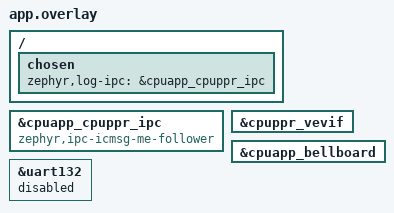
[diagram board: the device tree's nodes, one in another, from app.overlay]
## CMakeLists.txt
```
#
# Copyright (c) 2026 Nordic Semiconductor ASA
#
# SPDX-License-Identifier: LicenseRef-Nordic-5-Clause
#

cmake_minimum_required(VERSION 3.20.0)

find_package(Zephyr REQUIRED HINTS $ENV{ZEPHYR_BASE})
project("Asset Tracker Template PPR")

target_sources(app PRIVATE src/main.c)
```

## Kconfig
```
#
# Copyright (c) 2026 Nordic Semiconductor ASA
#
# SPDX-License-Identifier: LicenseRef-Nordic-5-Clause
#

config PPR_HELLO_INTERVAL_SECONDS
	int "Hello world interval (seconds)"
	default 5
	help
	  Interval between the "hello world" log messages printed by the PPR core.

source "Kconfig.zephyr"
```

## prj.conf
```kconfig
#
# Copyright (c) 2026 Nordic Semiconductor ASA
#
# SPDX-License-Identifier: LicenseRef-Nordic-5-Clause
#

# Logs are forwarded to the application core over IPC (icmsg-me).
CONFIG_LOG=y
CONFIG_LOG_BACKEND_IPC_SERVICE=y
CONFIG_IPC_SERVICE=y
CONFIG_MBOX=y
CONFIG_OPENAMP=n
CONFIG_PM=n

# Name reported to the application core, used as the "cpuppr/" log line prefix.
CONFIG_LOG_DOMAIN_NAME="cpuppr"

# Must run after the icmsg workqueue is started (CONFIG_KERNEL_INIT_PRIORITY_DEFAULT).
# The backend enables the mbox RX callback at init, and an interrupt before the
# workqueue exists trips an assert in icmsg.c.
CONFIG_LOG_CORE_INIT_PRIORITY=47

# Keep RAM use low, the PPR runs from its 64 KB TCM (CONFIG_XIP=n).
#
# Deferred log mode (the default) is required: the IPC backend only becomes ready
# after an asynchronous handshake with the application core, and only the log
# processing thread retries activating it.
CONFIG_LOG_BUFFER_SIZE=256
CONFIG_LOG_PROCESS_THREAD_STACK_SIZE=640
CONFIG_HEAP_MEM_POOL_SIZE=256

# Output goes over IPC only. No UART console on the PPR.
CONFIG_SERIAL=n
CONFIG_CONSOLE=n
CONFIG_UART_CONSOLE=n
```

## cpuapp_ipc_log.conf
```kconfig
#
# Copyright (c) 2026 Nordic Semiconductor ASA
#
# SPDX-License-Identifier: LicenseRef-Nordic-5-Clause
#

# Application core side of the PPR log forwarding. Added to the application image
# by app/sysbuild.cmake when SB_CONFIG_LAUNCH_PPR is enabled.

CONFIG_LOG=y
CONFIG_LOG_MULTIDOMAIN=y
CONFIG_LOG_LINK_IPC_SERVICE=y
CONFIG_IPC_SERVICE=y
CONFIG_MBOX=y

# Prefix each log line with the core it came from ("cpuapp/" or "cpuppr/").
# The PPR core's name is fetched over the same IPC link.
CONFIG_LOG_DOMAIN_NAME_PREFIX=y
CONFIG_LOG_DOMAIN_NAME="cpuapp"

# The log link init must run after both the VPR launcher that starts the PPR core
# (CONFIG_NORDIC_VPR_LAUNCHER_INIT_PRIORITY, default 0) and the icmsg-me backend
# init (CONFIG_IPC_SERVICE_REG_BACKEND_PRIORITY, default 46). Otherwise the link
# waits forever for a core that was never launched, or races the backend init.
CONFIG_LOG_CORE_INIT_PRIORITY=47
```

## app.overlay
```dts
/*
 * Copyright (c) 2026 Nordic Semiconductor ASA
 *
 * SPDX-License-Identifier: LicenseRef-Nordic-5-Clause
 */

/* Follower side of the icmsg-me log channel, see ../cpuapp_ipc_log.overlay. */
&cpuapp_cpuppr_ipc {
	compatible = "zephyr,ipc-icmsg-me-follower";
	status = "okay";
};

&cpuppr_vevif {
	status = "okay";
};

&cpuapp_bellboard {
	status = "okay";
};

/ {
	chosen {
		zephyr,log-ipc = &cpuapp_cpuppr_ipc;
		/delete-property/ zephyr,console;
	};
};

/* The PPR has no UART console, logs are forwarded over IPC. Keeps uart132 free
 * for the application domain (MCUboot serial recovery).
 */
&uart132 {
	status = "disabled";
};
```

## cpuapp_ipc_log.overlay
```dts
/*
 * Copyright (c) 2026 Nordic Semiconductor ASA
 *
 * SPDX-License-Identifier: LicenseRef-Nordic-5-Clause
 *
 * Application core side of the PPR log forwarding. Added to the application image
 * by app/sysbuild.cmake when SB_CONFIG_LAUNCH_PPR is enabled.
 */

/* Launch the PPR core. The board DTS already sets execution-memory and
 * source-memory, so CONFIG_NORDIC_VPR_LAUNCHER is enabled automatically.
 */
&cpuppr_vpr {
	status = "okay";
};

/* Multi-endpoint icmsg, so more endpoints can share the channel with the
 * "logging" endpoint registered by CONFIG_LOG_LINK_IPC_SERVICE.
 */
&cpuapp_cpuppr_ipc {
	compatible = "zephyr,ipc-icmsg-me-initiator";
	status = "okay";
};

&cpuppr_vevif {
	status = "okay";
};

&cpuapp_bellboard {
	status = "okay";
};

/ {
	chosen {
		zephyr,log-ipc = &cpuapp_cpuppr_ipc;
	};
};
```

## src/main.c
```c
/*
 * Copyright (c) 2026 Nordic Semiconductor ASA
 *
 * SPDX-License-Identifier: LicenseRef-Nordic-5-Clause
 */

#include <zephyr/kernel.h>
#include <zephyr/logging/log.h>

LOG_MODULE_REGISTER(main, LOG_LEVEL_INF);

int main(void)
{
	while (true) {
		LOG_INF("hello world from %s", CONFIG_BOARD_TARGET);
		k_sleep(K_SECONDS(CONFIG_PPR_HELLO_INTERVAL_SECONDS));
	}

	return 0;
}
```
